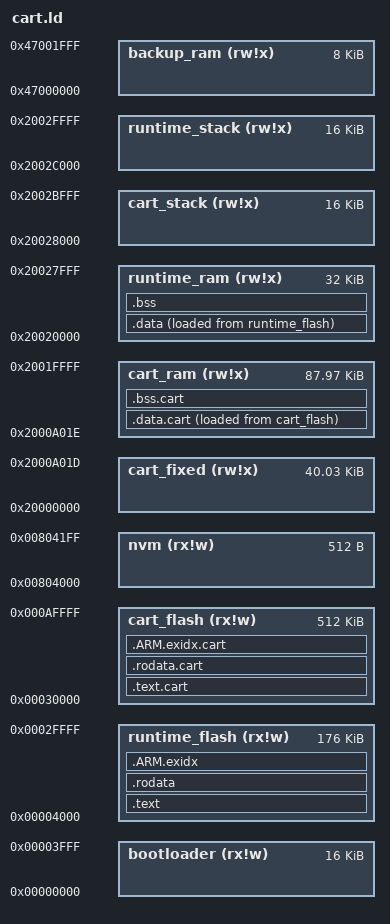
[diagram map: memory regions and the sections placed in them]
/*
 * This file was auto-generated by microzig, and then modified with black magic
 *
 * Target CPU:  ARM Cortex-M4
 * Target Chip: ATSAMD51J19A
 */

ENTRY(microzig_main);

MEMORY
{
  bootloader    (rx!w) : ORIGIN = 0x00000000, LENGTH = 0x00004000
  runtime_flash (rx!w) : ORIGIN = 0x00004000, LENGTH = 0x0002C000
  cart_flash    (rx!w) : ORIGIN = 0x00030000, LENGTH = 0x00080000
  cart_fixed    (rw!x) : ORIGIN = 0x20000000, LENGTH = 0x0000A01E
  cart_ram      (rw!x) : ORIGIN = 0x2000A01E, LENGTH = 0x00015FE2
  runtime_ram   (rw!x) : ORIGIN = 0x20020000, LENGTH = 0x00008000
  cart_stack    (rw!x) : ORIGIN = 0x20028000, LENGTH = 0x00004000
  runtime_stack (rw!x) : ORIGIN = 0x2002C000, LENGTH = 0x00004000
  backup_ram    (rw!x) : ORIGIN = 0x47000000, LENGTH = 0x00002000
  nvm           (rx!w) : ORIGIN = 0x00804000, LENGTH = 0x00000200
}

SECTIONS
{
  .text.cart : {
    *libcart.a:*(.text*)
    *libc.a:*(.text*)
    *libcompiler_rt.a:*(.text*)
    *(.text.cart)
  } >cart_flash

  .rodata.cart : {
    *libcart.a:*(.rodata*)
    *libc.a:*(.rodata*)
    *libcompiler_rt.a:*(.rodata*)
  } >cart_flash

  .ARM.exidx.cart : {
    *libcart.a:*(.ARM.exidx* .gnu.linkonce.armexidx.*)
    *libc.a:*(.ARM.exidx* .gnu.linkonce.armexidx.*)
    *libcompiler_rt.a:*(.ARM.exidx* .gnu.linkonce.armexidx.*)
  } >cart_flash

  .data.cart : {
    cart_data_load_start = LOADADDR(.data.cart);
    cart_data_start = .;
    *libcart.a:*(.data*)
    *libc.a:*(.data*)
    *libcompiler_rt.a:*(.data*)
    cart_data_end = .;
  } >cart_ram AT>cart_flash

  .bss.cart (NOLOAD) : {
    cart_bss_start = .;
    *libcart.a:*(.bss*)
    *libc.a:*(.bss*)
    *libcompiler_rt.a:*(.bss*)
    cart_bss_end = .;
  } >cart_ram

  .text : {
    KEEP(*(microzig_flash_start))
    *(.text*)
  } >runtime_flash

  .rodata : {
    *(.rodata*)
  } >runtime_flash

  .ARM.exidx : {
    *(.ARM.exidx* .gnu.linkonce.armexidx.*)
  } >runtime_flash

  .data : {
    microzig_data_load_start = LOADADDR(.data);
    microzig_data_start = .;
    *(.data*)
    microzig_data_end = .;
  } >runtime_ram AT>runtime_flash

  .bss (NOLOAD) : {
    microzig_bss_start = .;
    *(.bss*)
    microzig_bss_end = .;
  } >runtime_ram
}
